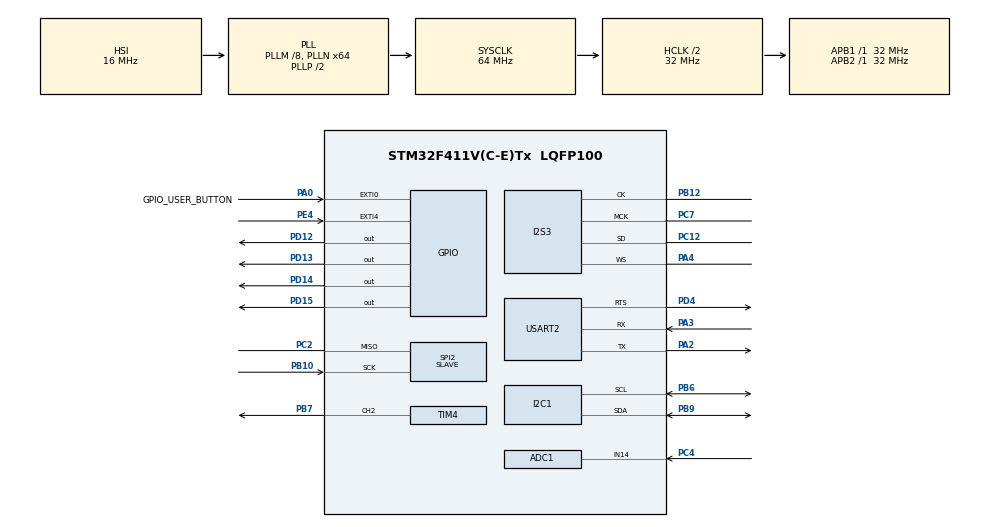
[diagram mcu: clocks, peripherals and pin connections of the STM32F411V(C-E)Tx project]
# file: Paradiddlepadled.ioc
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ADC1.Channel-3\#ChannelRegularConversion=ADC_CHANNEL_14
ADC1.ContinuousConvMode=ENABLE
ADC1.EOCSelection=ADC_EOC_SEQ_CONV
ADC1.EnableAnalogWatchDog=true
ADC1.HighThreshold=20
ADC1.ITMode=ENABLE
ADC1.InjNumberOfConversion=0
ADC1.LowThreshold=0
ADC1.NbrOfConversion=1
ADC1.NbrOfConversionFlag=1
ADC1.Rank-3\#ChannelRegularConversion=1
ADC1.Resolution=ADC_RESOLUTION_6B
ADC1.SamplingTime-3\#ChannelRegularConversion=ADC_SAMPLETIME_480CYCLES
ADC1.WatchdogChannel=ADC_CHANNEL_14
ADC1.master=1
Dma.Request0=SPI3_TX
Dma.Request1=TIM4_CH2
Dma.SPI3_TX.0.Direction=DMA_MEMORY_TO_PERIPH
Dma.SPI3_TX.0.FIFOMode=DMA_FIFOMODE_ENABLE
Dma.SPI3_TX.0.FIFOThreshold=DMA_FIFO_THRESHOLD_FULL
Dma.SPI3_TX.0.Instance=DMA1_Stream5
Dma.SPI3_TX.0.MemBurst=DMA_MBURST_SINGLE
Dma.SPI3_TX.0.MemDataAlignment=DMA_MDATAALIGN_HALFWORD
Dma.SPI3_TX.0.MemInc=DMA_MINC_ENABLE
Dma.SPI3_TX.0.Mode=DMA_NORMAL
Dma.SPI3_TX.0.PeriphBurst=DMA_PBURST_SINGLE
Dma.SPI3_TX.0.PeriphDataAlignment=DMA_PDATAALIGN_HALFWORD
Dma.SPI3_TX.0.PeriphInc=DMA_PINC_DISABLE
Dma.SPI3_TX.0.Priority=DMA_PRIORITY_LOW
Dma.TIM4_CH2.1.Direction=DMA_MEMORY_TO_PERIPH
Dma.TIM4_CH2.1.FIFOMode=DMA_FIFOMODE_DISABLE
Dma.TIM4_CH2.1.Instance=DMA1_Stream3
Dma.TIM4_CH2.1.MemDataAlignment=DMA_MDATAALIGN_HALFWORD
Dma.TIM4_CH2.1.MemInc=DMA_MINC_ENABLE
Dma.TIM4_CH2.1.Mode=DMA_CIRCULAR
Dma.TIM4_CH2.1.PeriphDataAlignment=DMA_PDATAALIGN_HALFWORD
Dma.TIM4_CH2.1.PeriphInc=DMA_PINC_DISABLE
Dma.TIM4_CH2.1.Priority=DMA_PRIORITY_LOW
I2S3.ErrorAudioFreq=-0.27 %
I2S3.FullDuplexMode=I2S_FULLDUPLEXMODE_DISABLE
I2S3.Instance=SPI$Index
I2S3.RealAudioFreq=7.978 KHz
I2S3.VirtualMode=I2S_MODE_MASTER
Mcu.Family=STM32F4
Mcu.Name=STM32F411V(C-E)Tx
Mcu.Package=LQFP100
NVIC.ADC_IRQn=true\:0\:0\:false\:false\:true\:true\:true\:true
NVIC.DMA1_Stream3_IRQn=true\:0\:0\:false\:false\:true\:false\:true\:true
NVIC.DMA1_Stream5_IRQn=true\:0\:0\:false\:false\:true\:false\:true\:true
NVIC.EXTI0_IRQn=true\:0\:0\:false\:false\:true\:true\:true\:true
NVIC.EXTI4_IRQn=true\:0\:0\:false\:false\:true\:true\:true\:true
NVIC.PriorityGroup=NVIC_PRIORITYGROUP_4
NVIC.TIM2_IRQn=true\:0\:0\:false\:false\:true\:true\:true\:true
NVIC.TIM3_IRQn=true\:0\:0\:false\:false\:true\:true\:true\:true
NVIC.TIM4_IRQn=true\:0\:0\:false\:false\:true\:true\:true\:true
PA0-WKUP.GPIO_Label=GPIO_USER_BUTTON
PA0-WKUP.GPIO_ModeDefaultEXTI=GPIO_MODE_IT_RISING_FALLING
PA0-WKUP.Signal=GPXTI0
PA2.Mode=Asynchronous
PA2.Signal=USART2_TX
PA3.Mode=Asynchronous
PA3.Signal=USART2_RX
PA4.Mode=Half_Duplex_Master
PA4.Signal=I2S3_WS
PB10.Mode=Simplex_Bidirectional_Slave
PB10.Signal=SPI2_SCK
PB12.Mode=Half_Duplex_Master
PB12.Signal=I2S3_CK
PB6.Mode=I2C
PB6.Signal=I2C1_SCL
PB7.Signal=S_TIM4_CH2
PB9.Mode=I2C
PB9.Signal=I2C1_SDA
PC12.Mode=Half_Duplex_Master
PC12.Signal=I2S3_SD
PC2.Mode=Simplex_Bidirectional_Slave
PC2.Signal=SPI2_MISO
PC4.GPIO_Mode=GPIO_MODE_ANALOG
PC4.GPIO_PuPd=GPIO_NOPULL
PC4.Signal=ADCx_IN14
PC7.Mode=Master_Clock_Activated
PC7.Signal=I2S3_MCK
PD12.Signal=GPIO_Output
PD13.Signal=GPIO_Output
PD14.Signal=GPIO_Output
PD15.Signal=GPIO_Output
PD4.Mode=RTS_Only
PD4.Signal=USART2_RTS
PE4.Signal=GPXTI4
ProjectManager.HeapSize=0x200
ProjectManager.StackSize=0x400
ProjectManager.TargetToolchain=STM32CubeIDE
RCC.48MHZClocksFreq_Value=32000000
RCC.AHBCLKDivider=RCC_SYSCLK_DIV2
RCC.AHBFreq_Value=32000000
RCC.APB1Freq_Value=32000000
RCC.APB1TimFreq_Value=32000000
RCC.APB2Freq_Value=32000000
RCC.APB2TimFreq_Value=32000000
RCC.CortexFreq_Value=32000000
RCC.HCLKFreq_Value=32000000
RCC.HSE_VALUE=25000000
RCC.HSI_VALUE=16000000
RCC.LSE_VALUE=32768
RCC.PLLM=8
RCC.PLLN=64
RCC.SYSCLKFreq_VALUE=64000000
RCC.SYSCLKSource=RCC_SYSCLKSOURCE_PLLCLK
RCC.VCOOutputFreq_Value=128000000
SH.ADCx_IN14.0=ADC1_IN14,IN14
SH.S_TIM4_CH2.0=TIM4_CH2,PWM Generation2 CH2
SPI2.Direction=SPI_DIRECTION_1LINE
SPI2.Mode=SPI_MODE_SLAVE
SPI2.VirtualType=VM_SLAVE
TIM2.Channel-PWM\ Generation1\ No\ Output=TIM_CHANNEL_1
TIM2.CounterMode=TIM_COUNTERMODE_UP
TIM2.Period=16000000
TIM2.Prescaler=0
TIM2.Pulse-PWM\ Generation1\ No\ Output=4000000
TIM2.TIM_MasterOutputTrigger=TIM_TRGO_OC1REF
TIM3.Channel-PWM\ Generation1\ No\ Output=TIM_CHANNEL_1
TIM3.Period=3
TIM3.Pulse-PWM\ Generation1\ No\ Output=1
TIM4.Channel-PWM\ Generation2\ CH2=TIM_CHANNEL_2
TIM4.Period=40
USART2.VirtualMode=VM_ASYNC
VP_TIM2_VS_ClockSourceINT.Mode=Internal
VP_TIM2_VS_no_output1.Mode=PWM Generation1 No Output
VP_TIM3_VS_ClockSourceITR.Mode=TriggerSource_ITR1
VP_TIM3_VS_ControllerModeClock.Mode=Clock Mode
VP_TIM3_VS_no_output1.Mode=PWM Generation1 No Output
VP_TIM4_VS_ClockSourceINT.Mode=Internal
board=custom

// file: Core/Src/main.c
/* USER CODE BEGIN Header */
/**
  ******************************************************************************
  * @file           : main.c
  * @brief          : Main program body
  ******************************************************************************
  * @attention
  *
  * Copyright (c) 2022 STMicroelectronics.
  * All rights reserved.
  *
  * This software is licensed under terms that can be found in the LICENSE file
  * in the root directory of this software component.
  * If no LICENSE file comes with this software, it is provided AS-IS.
  *
  ******************************************************************************
  */
/* USER CODE END Header */
#include "main.h"
#include "adc.h"
#include "dma.h"
#include "i2c.h"
#include "i2s.h"
#include "spi.h"
#include "tim.h"
#include "usart.h"
#include "gpio.h"

void SystemClock_Config(void);

/* USER CODE BEGIN 0 */
void paradiddlepadled_main(void);
/* USER CODE END 0 */

int main(void)
{

  /* MCU Configuration--------------------------------------------------------*/

  /* Reset of all peripherals, Initializes the Flash interface and the Systick. */
  HAL_Init();

  /* Configure the system clock */
  SystemClock_Config();

  /* Initialize all configured peripherals */
  MX_GPIO_Init();
  MX_DMA_Init();
  MX_USART2_UART_Init();
  MX_TIM2_Init();
  MX_TIM3_Init();
  MX_ADC1_Init();
  MX_SPI2_Init();
  MX_I2S3_Init();
  MX_I2C1_Init();
  MX_TIM4_Init();
  /* USER CODE BEGIN 2 */
  paradiddlepadled_main();
  /* USER CODE END 2 */

  /* Infinite loop */
  while (1)
  {

  }
}

void SystemClock_Config(void)
{
  RCC_OscInitTypeDef RCC_OscInitStruct = {0};
  RCC_ClkInitTypeDef RCC_ClkInitStruct = {0};

  /** Configure the main internal regulator output voltage
  */
  __HAL_RCC_PWR_CLK_ENABLE();
  __HAL_PWR_VOLTAGESCALING_CONFIG(PWR_REGULATOR_VOLTAGE_SCALE1);

  /** Initializes the RCC Oscillators according to the specified parameters
  * in the RCC_OscInitTypeDef structure.
  */
  RCC_OscInitStruct.OscillatorType = RCC_OSCILLATORTYPE_HSI;
  RCC_OscInitStruct.HSIState = RCC_HSI_ON;
  RCC_OscInitStruct.HSICalibrationValue = RCC_HSICALIBRATION_DEFAULT;
  RCC_OscInitStruct.PLL.PLLState = RCC_PLL_ON;
  RCC_OscInitStruct.PLL.PLLSource = RCC_PLLSOURCE_HSI;
  RCC_OscInitStruct.PLL.PLLM = 8;
  RCC_OscInitStruct.PLL.PLLN = 64;
  RCC_OscInitStruct.PLL.PLLP = RCC_PLLP_DIV2;
  RCC_OscInitStruct.PLL.PLLQ = 4;
  if (HAL_RCC_OscConfig(&RCC_OscInitStruct) != HAL_OK)
  {
    Error_Handler();
  }

  /** Initializes the CPU, AHB and APB buses clocks
  */
  RCC_ClkInitStruct.ClockType = RCC_CLOCKTYPE_HCLK|RCC_CLOCKTYPE_SYSCLK
                              |RCC_CLOCKTYPE_PCLK1|RCC_CLOCKTYPE_PCLK2;
  RCC_ClkInitStruct.SYSCLKSource = RCC_SYSCLKSOURCE_PLLCLK;
  RCC_ClkInitStruct.AHBCLKDivider = RCC_SYSCLK_DIV2;
  RCC_ClkInitStruct.APB1CLKDivider = RCC_HCLK_DIV1;
  RCC_ClkInitStruct.APB2CLKDivider = RCC_HCLK_DIV1;

  if (HAL_RCC_ClockConfig(&RCC_ClkInitStruct, FLASH_LATENCY_1) != HAL_OK)
  {
    Error_Handler();
  }
}

void Error_Handler(void)
{
  __disable_irq();
  while (1)
  {
  }
}
